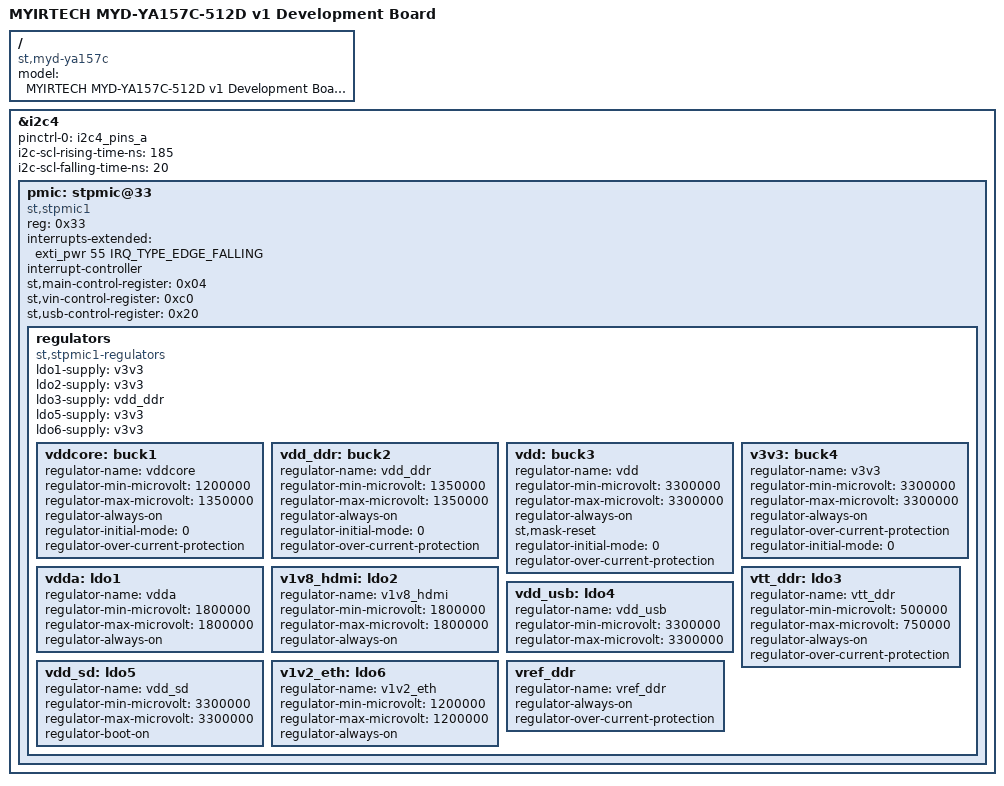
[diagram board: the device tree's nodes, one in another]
// SPDX-License-Identifier: (GPL-2.0+ OR BSD-3-Clause)
/*
 * Copyright (C) STMicroelectronics 2018 - All Rights Reserved
 * Author: Alexandre Torgue <alexandre.torgue@st.com>.
 */

/dts-v1/;

#include "stm32mp157c-ya157c.dts"


/ {
	model = "MYIRTECH MYD-YA157C-512D v1 Development Board";
	compatible = "st,myd-ya157c", "st,stm32mp157";

};

 /* ATF Specific */
 #include <dt-bindings/clock/stm32mp1-clksrc.h>
 #include <dt-bindings/power/stm32mp1-power.h>
  
/*512MBDDR*/
#include "stm32mp15-ddr3-2x2Gb-1066-binG.dtsi"
#include "stm32mp157c-security.dtsi"



&i2c4 {
	pinctrl-names = "default";
	pinctrl-0 = <&i2c4_pins_a>;
	i2c-scl-rising-time-ns = <185>;
	i2c-scl-falling-time-ns = <20>;
	status = "okay";

	pmic: stpmic@33 {
		compatible = "st,stpmic1";
		reg = <0x33>;
		interrupts-extended = <&exti_pwr 55 IRQ_TYPE_EDGE_FALLING>;
		interrupt-controller;
		#interrupt-cells = <2>;
		status = "okay";

		st,main-control-register = <0x04>;
		st,vin-control-register = <0xc0>;
		st,usb-control-register = <0x20>;

		regulators {
			compatible = "st,stpmic1-regulators";

			ldo1-supply = <&v3v3>;
			ldo2-supply = <&v3v3>;
			ldo3-supply = <&vdd_ddr>;
			ldo5-supply = <&v3v3>;
			ldo6-supply = <&v3v3>;

			vddcore: buck1 {
				regulator-name = "vddcore";
				regulator-min-microvolt = <1200000>;
				regulator-max-microvolt = <1350000>;
				regulator-always-on;
				regulator-initial-mode = <0>;
				regulator-over-current-protection;
			};

			vdd_ddr: buck2 {
				regulator-name = "vdd_ddr";
				regulator-min-microvolt = <1350000>;
				regulator-max-microvolt = <1350000>;
				regulator-always-on;
				regulator-initial-mode = <0>;
				regulator-over-current-protection;
			};

			vdd: buck3 {
				regulator-name = "vdd";
				regulator-min-microvolt = <3300000>;
				regulator-max-microvolt = <3300000>;
				regulator-always-on;
				st,mask-reset;
				regulator-initial-mode = <0>;
				regulator-over-current-protection;
			};

			v3v3: buck4 {
				regulator-name = "v3v3";
				regulator-min-microvolt = <3300000>;
				regulator-max-microvolt = <3300000>;
				regulator-always-on;
				regulator-over-current-protection;
				regulator-initial-mode = <0>;
			};

			vdda: ldo1 {
				regulator-name = "vdda";
				regulator-min-microvolt = <1800000>;
				regulator-max-microvolt = <1800000>;
				regulator-always-on;
			};

			v1v8_hdmi: ldo2 {
				regulator-name = "v1v8_hdmi";
				regulator-min-microvolt = <1800000>;
				regulator-max-microvolt = <1800000>;
				regulator-always-on;
			};

			vtt_ddr: ldo3 {
				regulator-name = "vtt_ddr";
				regulator-min-microvolt = <500000>;
				regulator-max-microvolt = <750000>;
				regulator-always-on;
				regulator-over-current-protection;
			};

			vdd_usb: ldo4 {
				regulator-name = "vdd_usb";
				regulator-min-microvolt = <3300000>;
				regulator-max-microvolt = <3300000>;
			};

			vdd_sd: ldo5 {
				regulator-name = "vdd_sd";
				regulator-min-microvolt = <3300000>;
				regulator-max-microvolt = <3300000>;
				regulator-boot-on;
			};

			v1v2_eth: ldo6 {
				regulator-name = "v1v2_eth";
				regulator-min-microvolt = <1200000>;
				regulator-max-microvolt = <1200000>;
				regulator-always-on;
			};

			vref_ddr: vref_ddr {
				regulator-name = "vref_ddr";
				regulator-always-on;
				regulator-over-current-protection;
			};
		};
	};
};
